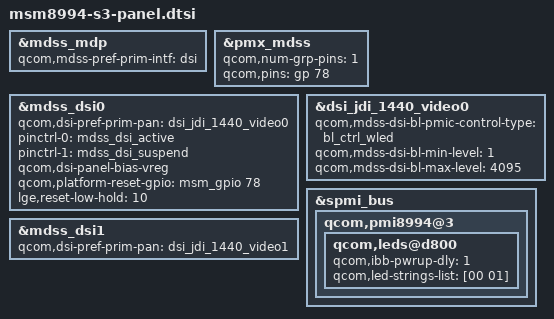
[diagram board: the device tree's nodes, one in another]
/* Copyright (c) 2014, The Linux Foundation. All rights reserved.
 *
 * This program is free software; you can redistribute it and/or modify
 * it under the terms of the GNU General Public License version 2 and
 * only version 2 as published by the Free Software Foundation.
 *
 * This program is distributed in the hope that it will be useful,
 * but WITHOUT ANY WARRANTY; without even the implied warranty of
 * MERCHANTABILITY or FITNESS FOR A PARTICULAR PURPOSE.  See the
 * GNU General Public License for more details.
 */

#include "../dsi-panel-jdi-dualmipi0-wqhd-video.dtsi"
#include "../dsi-panel-jdi-dualmipi1-wqhd-video.dtsi"
&mdss_mdp {
	qcom,mdss-pref-prim-intf = "dsi";
};

&pmx_mdss {
	qcom,num-grp-pins = <1>;
	qcom,pins = <&gp 78>;
};

&mdss_dsi0 {
	qcom,dsi-pref-prim-pan = <&dsi_jdi_1440_video0>;
	pinctrl-names = "mdss_default", "mdss_sleep";
	pinctrl-0 = <&mdss_dsi_active>;
	pinctrl-1 = <&mdss_dsi_suspend>;
	qcom,dsi-panel-bias-vreg;
	qcom,platform-reset-gpio = <&msm_gpio 78 0>;
	lge,reset-low-hold = <10>;
};

&mdss_dsi1 {
	qcom,dsi-pref-prim-pan = <&dsi_jdi_1440_video1>;
};

&dsi_jdi_1440_video0{
	qcom,mdss-dsi-bl-pmic-control-type = "bl_ctrl_wled";
	qcom,mdss-dsi-bl-min-level = <1>;
	qcom,mdss-dsi-bl-max-level = <4095>;
};

&spmi_bus {
	qcom,pmi8994@3 {
		qcom,leds@d800 {
	                qcom,ibb-pwrup-dly = <1>;
			qcom,led-strings-list = [00 01];
		};
	};
};
